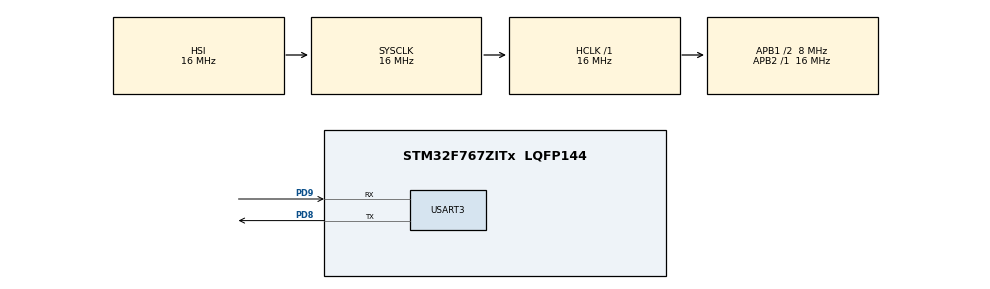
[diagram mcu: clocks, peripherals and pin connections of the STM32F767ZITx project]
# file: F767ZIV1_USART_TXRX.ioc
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Mcu.Family=STM32F7
NVIC.USART3_IRQn=true\:0\:0\:false\:false\:true\:true\:true
RCC.CortexFreq_Value=16000000
RCC.SYSCLKSourceVirtual=RCC_SYSCLKSOURCE_PLLCLK
PD9.Signal=USART3_RX
RCC.APB1CLKDivider=RCC_HCLK_DIV2
PD9.Mode=Asynchronous
ProjectManager.StackSize=0x400
USART3.VirtualMode-Asynchronous=VM_ASYNC
PA13.Signal=SYS_JTMS-SWDIO
ProjectManager.TargetToolchain=STM32CubeIDE
RCC.HCLKFreq_Value=16000000
RCC.APB2TimFreq_Value=16000000
PD8.Signal=USART3_TX
RCC.USBFreq_Value=96000000
RCC.LSE_VALUE=32768
PD8.Mode=Asynchronous
RCC.AHBFreq_Value=16000000
RCC.HSE_VALUE=16000000
board=NUCLEO-F767ZI
RCC.VCOOutputFreq_Value=192000000
RCC.PLLMUL=RCC_PLL_MUL9
RCC.APB2Freq_Value=16000000
RCC.PRESCALERUSB=RCC_USBCLKSOURCE_PLL_DIV1_5
PA14.Mode=Serial_Wire
PA13.Mode=Serial_Wire
Mcu.Name=STM32F767ZITx
RCC.48MHZClocksFreq_Value=24000000
RCC.SYSCLKFreq_VALUE=16000000
Mcu.Package=LQFP144
PA14.Signal=SYS_JTCK-SWCLK
ProjectManager.HeapSize=0x200
RCC.HSI_VALUE=16000000
NVIC.PriorityGroup=NVIC_PRIORITYGROUP_4
RCC.APB1TimFreq_Value=16000000
RCC.APB1Freq_Value=8000000

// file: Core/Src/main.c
/* USER CODE BEGIN Header */
/**
  ******************************************************************************
  * @file           : main.c
  * @brief          : Main program body
  ******************************************************************************
  * @attention
  *
  * <h2><center>&copy; Copyright (c) 2021 STMicroelectronics.
  * All rights reserved.</center></h2>
  *
  * This software component is licensed by ST under BSD 3-Clause license,
  * the "License"; You may not use this file except in compliance with the
  * License. You may obtain a copy of the License at:
  *                        opensource.org/licenses/BSD-3-Clause
  *
  ******************************************************************************
  */
/* USER CODE END Header */
#include "main.h"
#include <string.h>

UART_HandleTypeDef huart3;

void SystemClock_Config(void);
static void MX_GPIO_Init(void);
static void MX_USART3_UART_Init(void);

/* USER CODE BEGIN 0 */
uint8_t send_msg[24] = "Hello from the board\n\r";
uint8_t recv_msg[24] = "Hello from the board\n\r";
/* USER CODE END 0 */

int main(void)
{

  /* MCU Configuration--------------------------------------------------------*/

  /* Reset of all peripherals, Initializes the Flash interface and the Systick. */
  HAL_Init();

  /* Configure the system clock */
  SystemClock_Config();

  /* Initialize all configured peripherals */
  MX_GPIO_Init();
  MX_USART3_UART_Init();
  /* USER CODE BEGIN 2 */
  /* Enable the UART interrupt handler */
  __HAL_UART_ENABLE_IT(&huart3, UART_IT_RXNE);
  uint8_t ch[] = "\n\r";
  /* USER CODE END 2 */

  /* Infinite loop */
  /* USER CODE BEGIN WHILE */
  while (1)
     {
         /* Evaluate if the received string is not empty */
         if(strcmp(send_msg, recv_msg) != 0)
         {
             /* concatenate \n\r */
             strncat(recv_msg, &ch, 4);
             /* replace the send msg with the receive msg */
             strcpy(send_msg, recv_msg);
         }

         HAL_UART_Transmit(&huart3, send_msg, sizeof(send_msg), 100);
         HAL_Delay(1000);
     }
  /* USER CODE END 3 */
}

void SystemClock_Config(void)
{
  RCC_OscInitTypeDef RCC_OscInitStruct = {0};
  RCC_ClkInitTypeDef RCC_ClkInitStruct = {0};
  RCC_PeriphCLKInitTypeDef PeriphClkInitStruct = {0};

  /** Configure the main internal regulator output voltage
  */
  __HAL_RCC_PWR_CLK_ENABLE();
  __HAL_PWR_VOLTAGESCALING_CONFIG(PWR_REGULATOR_VOLTAGE_SCALE3);
  /** Initializes the RCC Oscillators according to the specified parameters
  * in the RCC_OscInitTypeDef structure.
  */
  RCC_OscInitStruct.OscillatorType = RCC_OSCILLATORTYPE_HSI;
  RCC_OscInitStruct.HSIState = RCC_HSI_ON;
  RCC_OscInitStruct.HSICalibrationValue = RCC_HSICALIBRATION_DEFAULT;
  RCC_OscInitStruct.PLL.PLLState = RCC_PLL_NONE;
  if (HAL_RCC_OscConfig(&RCC_OscInitStruct) != HAL_OK)
  {
    Error_Handler();
  }
  /** Initializes the CPU, AHB and APB buses clocks
  */
  RCC_ClkInitStruct.ClockType = RCC_CLOCKTYPE_HCLK|RCC_CLOCKTYPE_SYSCLK
                              |RCC_CLOCKTYPE_PCLK1|RCC_CLOCKTYPE_PCLK2;
  RCC_ClkInitStruct.SYSCLKSource = RCC_SYSCLKSOURCE_HSI;
  RCC_ClkInitStruct.AHBCLKDivider = RCC_SYSCLK_DIV1;
  RCC_ClkInitStruct.APB1CLKDivider = RCC_HCLK_DIV2;
  RCC_ClkInitStruct.APB2CLKDivider = RCC_HCLK_DIV1;

  if (HAL_RCC_ClockConfig(&RCC_ClkInitStruct, FLASH_LATENCY_0) != HAL_OK)
  {
    Error_Handler();
  }
  PeriphClkInitStruct.PeriphClockSelection = RCC_PERIPHCLK_USART3;
  PeriphClkInitStruct.Usart3ClockSelection = RCC_USART3CLKSOURCE_PCLK1;
  if (HAL_RCCEx_PeriphCLKConfig(&PeriphClkInitStruct) != HAL_OK)
  {
    Error_Handler();
  }
}

static void MX_USART3_UART_Init(void)
{

  huart3.Instance = USART3;
  huart3.Init.BaudRate = 115200;
  huart3.Init.WordLength = UART_WORDLENGTH_8B;
  huart3.Init.StopBits = UART_STOPBITS_1;
  huart3.Init.Parity = UART_PARITY_NONE;
  huart3.Init.Mode = UART_MODE_TX_RX;
  huart3.Init.HwFlowCtl = UART_HWCONTROL_NONE;
  huart3.Init.OverSampling = UART_OVERSAMPLING_16;
  huart3.Init.OneBitSampling = UART_ONE_BIT_SAMPLE_DISABLE;
  huart3.AdvancedInit.AdvFeatureInit = UART_ADVFEATURE_NO_INIT;
  if (HAL_UART_Init(&huart3) != HAL_OK)
  {
    Error_Handler();
  }

}

static void MX_GPIO_Init(void)
{

  /* GPIO Ports Clock Enable */
  __HAL_RCC_GPIOD_CLK_ENABLE();
  __HAL_RCC_GPIOA_CLK_ENABLE();

}

void Error_Handler(void)
{
  __disable_irq();
  while (1)
  {
  }
}

/************************ (C) COPYRIGHT STMicroelectronics *****END OF FILE****/
